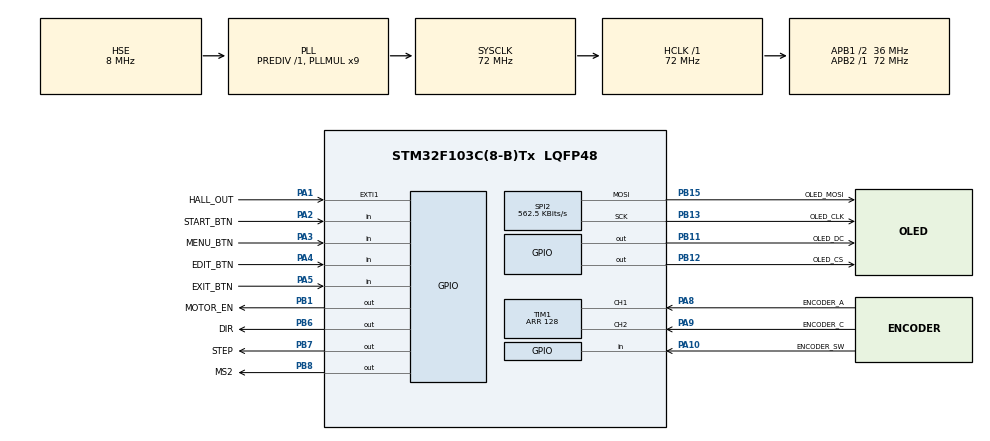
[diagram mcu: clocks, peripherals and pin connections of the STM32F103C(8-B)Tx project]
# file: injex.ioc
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FREERTOS.BinarySemaphores01=stopMoveByTime;suspendMoveByTime
FREERTOS.Queues01=buttonEvents,16,uint16_t,NULL;encoderEvents,16,uint16_t,NULL
FREERTOS.Tasks01=defaultTask,0,64,StartDefaultTask,Default;buttonScanTask,-2,128,buttonScanFunc,As external;guiTask,0,128,guiFunc,As external;motorTask,1,64,motorFunc,As external
FREERTOS.Timers01=elapsedTimer,elapsedTimerCallback,osTimerPeriodic,As external;moveTimer,moveTimerCallback,osTimerPeriodic,As external
FREERTOS.configMINIMAL_STACK_SIZE=64
FREERTOS.configTIMER_QUEUE_LENGTH=20
FREERTOS.configTIMER_TASK_PRIORITY=4
FREERTOS.configTOTAL_HEAP_SIZE=6072
FREERTOS.configUSE_TIMERS=1
Mcu.Family=STM32F1
Mcu.Name=STM32F103C(8-B)Tx
Mcu.Package=LQFP48
NVIC.EXTI1_IRQn=true\:7\:0\:true
NVIC.PriorityGroup=NVIC_PRIORITYGROUP_4
NVIC.TIM2_IRQn=true\:15\:0\:true
PA1.GPIO_Label=HALL_OUT
PA1.GPIO_ModeDefaultEXTI=GPIO_MODE_IT_RISING_FALLING
PA1.GPIO_PuPd=GPIO_PULLUP
PA1.Signal=GPXTI1
PA10.GPIO_Label=ENCODER_SW
PA10.GPIO_PuPd=GPIO_PULLDOWN
PA10.Signal=GPIO_Input
PA13.Mode=Serial_Wire
PA13.Signal=SYS_JTMS-SWDIO
PA14.Mode=Serial_Wire
PA14.Signal=SYS_JTCK-SWCLK
PA2.GPIO_Label=START_BTN
PA2.GPIO_PuPd=GPIO_PULLDOWN
PA2.Signal=GPIO_Input
PA3.GPIO_Label=MENU_BTN
PA3.GPIO_PuPd=GPIO_PULLDOWN
PA3.Signal=GPIO_Input
PA4.GPIO_Label=EDIT_BTN
PA4.GPIO_PuPd=GPIO_PULLDOWN
PA4.Signal=GPIO_Input
PA5.GPIO_Label=EXIT_BTN
PA5.GPIO_PuPd=GPIO_PULLDOWN
PA5.Signal=GPIO_Input
PA8.GPIO_Label=ENCODER_A
PA8.GPIO_PuPd=GPIO_PULLUP
PA8.Signal=S_TIM1_CH1
PA9.GPIO_Label=ENCODER_C
PA9.GPIO_PuPd=GPIO_PULLUP
PA9.Signal=S_TIM1_CH2
PB1.GPIO_Label=MOTOR_EN
PB1.GPIO_Speed=GPIO_SPEED_HIGH
PB1.Signal=GPIO_Output
PB11.GPIO_Label=OLED_DC
PB11.GPIO_Speed=GPIO_SPEED_HIGH
PB11.Signal=GPIO_Output
PB12.GPIO_Label=OLED_CS
PB12.GPIO_Speed=GPIO_SPEED_HIGH
PB12.Signal=GPIO_Output
PB13.GPIO_Label=OLED_CLK
PB13.Mode=TX_Only_Simplex_Unidirect_Master
PB13.Signal=SPI2_SCK
PB15.GPIO_Label=OLED_MOSI
PB15.Mode=TX_Only_Simplex_Unidirect_Master
PB15.Signal=SPI2_MOSI
PB6.GPIO_Label=DIR
PB6.GPIO_Speed=GPIO_SPEED_HIGH
PB6.Signal=GPIO_Output
PB7.GPIO_Label=STEP
PB7.GPIO_Speed=GPIO_SPEED_HIGH
PB7.Signal=GPIO_Output
PB8.GPIO_Label=MS2
PB8.GPIO_Speed=GPIO_SPEED_HIGH
PB8.Signal=GPIO_Output
PD0-OSC_IN.Mode=HSE-External-Oscillator
PD0-OSC_IN.Signal=RCC_OSC_IN
PD1-OSC_OUT.Mode=HSE-External-Oscillator
PD1-OSC_OUT.Signal=RCC_OSC_OUT
ProjectManager.HeapSize=0x400
ProjectManager.StackSize=0x200
ProjectManager.TargetToolchain=SW4STM32
RCC.AHBFreq_Value=72000000
RCC.APB1CLKDivider=RCC_HCLK_DIV2
RCC.APB1Freq_Value=36000000
RCC.APB1TimFreq_Value=72000000
RCC.APB2Freq_Value=72000000
RCC.APB2TimFreq_Value=72000000
RCC.HCLKFreq_Value=72000000
RCC.HSIState=RCC_HSI_ON
RCC.PLLMUL=RCC_PLL_MUL9
RCC.PLLSourceVirtual=RCC_PLLSOURCE_HSE
RCC.SYSCLKFreq_VALUE=72000000
RCC.SYSCLKSource=RCC_SYSCLKSOURCE_PLLCLK
RCC.USBFreq_Value=72000000
SH.S_TIM1_CH1.0=TIM1_CH1,Encoder_Interface
SH.S_TIM1_CH2.0=TIM1_CH2,Encoder_Interface
SPI2.BaudRatePrescaler=SPI_BAUDRATEPRESCALER_64
SPI2.CalculateBaudRate=562.5 KBits/s
SPI2.Mode=SPI_MODE_MASTER
TIM1.ClockDivision=TIM_CLOCKDIVISION_DIV2
TIM1.EncoderMode=TIM_ENCODERMODE_TI12
TIM1.IC1Filter=5
TIM1.IC1Polarity=TIM_ICPOLARITY_FALLING
TIM1.IC2Filter=5
TIM1.IC2Polarity=TIM_ICPOLARITY_FALLING
TIM1.Period=128
TIM2.Period=100
TIM2.Prescaler=720
VP_FREERTOS_VS_ENABLE.Mode=Enabled
VP_TIM2_VS_ClockSourceINT.Mode=Internal
board=injex

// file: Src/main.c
/**
  ******************************************************************************
  * File Name          : main.c
  * Description        : Main program body
  ******************************************************************************
  *
  * COPYRIGHT(c) 2016 STMicroelectronics
  *
  * Redistribution and use in source and binary forms, with or without modification,
  * are permitted provided that the following conditions are met:
  *   1. Redistributions of source code must retain the above copyright notice,
  *      this list of conditions and the following disclaimer.
  *   2. Redistributions in binary form must reproduce the above copyright notice,
  *      this list of conditions and the following disclaimer in the documentation
  *      and/or other materials provided with the distribution.
  *   3. Neither the name of STMicroelectronics nor the names of its contributors
  *      may be used to endorse or promote products derived from this software
  *      without specific prior written permission.
  *
  * THIS SOFTWARE IS PROVIDED BY THE COPYRIGHT HOLDERS AND CONTRIBUTORS "AS IS"
  * AND ANY EXPRESS OR IMPLIED WARRANTIES, INCLUDING, BUT NOT LIMITED TO, THE
  * IMPLIED WARRANTIES OF MERCHANTABILITY AND FITNESS FOR A PARTICULAR PURPOSE ARE
  * DISCLAIMED. IN NO EVENT SHALL THE COPYRIGHT HOLDER OR CONTRIBUTORS BE LIABLE
  * FOR ANY DIRECT, INDIRECT, INCIDENTAL, SPECIAL, EXEMPLARY, OR CONSEQUENTIAL
  * DAMAGES (INCLUDING, BUT NOT LIMITED TO, PROCUREMENT OF SUBSTITUTE GOODS OR
  * SERVICES; LOSS OF USE, DATA, OR PROFITS; OR BUSINESS INTERRUPTION) HOWEVER
  * CAUSED AND ON ANY THEORY OF LIABILITY, WHETHER IN CONTRACT, STRICT LIABILITY,
  * OR TORT (INCLUDING NEGLIGENCE OR OTHERWISE) ARISING IN ANY WAY OUT OF THE USE
  * OF THIS SOFTWARE, EVEN IF ADVISED OF THE POSSIBILITY OF SUCH DAMAGE.
  *
  ******************************************************************************
  */
#include "stm32f1xx_hal.h"
#include "cmsis_os.h"

/* USER CODE BEGIN Includes */
#include "motor_control.h"
#include "gui.h"
/* USER CODE END Includes */

SPI_HandleTypeDef hspi2;

TIM_HandleTypeDef htim1;
TIM_HandleTypeDef htim2;

osThreadId defaultTaskHandle;
osThreadId buttonScanTaskHandle;
osThreadId guiTaskHandle;
osThreadId motorTaskHandle;
osMessageQId buttonEventsHandle;
osMessageQId encoderEventsHandle;
osTimerId elapsedTimerHandle;
osTimerId moveTimerHandle;
osSemaphoreId stopMoveByTimeHandle;
osSemaphoreId suspendMoveByTimeHandle;

/* USER CODE BEGIN PV */
QueueHandle_t xInputEvents;
QueueHandle_t xMotorEvents;
/* Private variables ---------------------------------------------------------*/

/* USER CODE END PV */

void SystemClock_Config(void);
static void MX_GPIO_Init(void);
static void MX_SPI2_Init(void);
static void MX_TIM1_Init(void);
static void MX_TIM2_Init(void);
void StartDefaultTask(void const * argument);
extern void buttonScanFunc(void const * argument);
extern void guiFunc(void const * argument);
extern void motorFunc(void const * argument);
extern void elapsedTimerCallback(void const * argument);
extern void moveTimerCallback(void const * argument);

/* USER CODE BEGIN PFP */
/* Private function prototypes -----------------------------------------------*/
/* USER CODE END PFP */

int main(void)
{

  /* MCU Configuration----------------------------------------------------------*/

  /* Reset of all peripherals, Initializes the Flash interface and the Systick. */
  HAL_Init();

  /* Configure the system clock */
  SystemClock_Config();

  /* Initialize all configured peripherals */
  MX_GPIO_Init();
  MX_SPI2_Init();
  MX_TIM1_Init();
  MX_TIM2_Init();

  /* USER CODE BEGIN 2 */
	InitMotor();
	HAL_TIM_Encoder_Start(&htim1,TIM_CHANNEL_ALL);

  /* USER CODE END 2 */

  /* Create the semaphores(s) */
  /* definition and creation of stopMoveByTime */
  osSemaphoreDef(stopMoveByTime);
  stopMoveByTimeHandle = osSemaphoreCreate(osSemaphore(stopMoveByTime), 1);

  /* definition and creation of suspendMoveByTime */
  osSemaphoreDef(suspendMoveByTime);
  suspendMoveByTimeHandle = osSemaphoreCreate(osSemaphore(suspendMoveByTime), 1);

  /* USER CODE BEGIN RTOS_SEMAPHORES */
  xSemaphoreTake(stopMoveByTimeHandle, 0);
  xSemaphoreTake(suspendMoveByTimeHandle, 0);
	/* add semaphores, ... */
  /* USER CODE END RTOS_SEMAPHORES */

  /* Create the timer(s) */
  /* definition and creation of elapsedTimer */
  osTimerDef(elapsedTimer, elapsedTimerCallback);
  elapsedTimerHandle = osTimerCreate(osTimer(elapsedTimer), osTimerPeriodic, NULL);

  /* definition and creation of moveTimer */
  osTimerDef(moveTimer, moveTimerCallback);
  moveTimerHandle = osTimerCreate(osTimer(moveTimer), osTimerPeriodic, NULL);

  /* Create the thread(s) */
  /* definition and creation of defaultTask */
  osThreadDef(defaultTask, StartDefaultTask, osPriorityNormal, 0, 64);
  defaultTaskHandle = osThreadCreate(osThread(defaultTask), NULL);

  /* definition and creation of buttonScanTask */
  osThreadDef(buttonScanTask, buttonScanFunc, osPriorityLow, 0, 128);
  buttonScanTaskHandle = osThreadCreate(osThread(buttonScanTask), NULL);

  /* definition and creation of guiTask */
  osThreadDef(guiTask, guiFunc, osPriorityNormal, 0, 128);
  guiTaskHandle = osThreadCreate(osThread(guiTask), NULL);

  /* definition and creation of motorTask */
  osThreadDef(motorTask, motorFunc, osPriorityAboveNormal, 0, 64);
  motorTaskHandle = osThreadCreate(osThread(motorTask), NULL);

  /* Create the queue(s) */
  /* definition and creation of buttonEvents */
  osMessageQDef(buttonEvents, 16, uint16_t);
  buttonEventsHandle = osMessageCreate(osMessageQ(buttonEvents), NULL);

  /* definition and creation of encoderEvents */
  osMessageQDef(encoderEvents, 16, uint16_t);
  encoderEventsHandle = osMessageCreate(osMessageQ(encoderEvents), NULL);

  /* USER CODE BEGIN RTOS_QUEUES */
	/* add queues, ... */
  xInputEvents = xQueueCreate( 8, sizeof( struct Event ) );
  xMotorEvents = xQueueCreate( 4, sizeof( struct MotorEvent ) );
  /* USER CODE END RTOS_QUEUES */

  /* Start scheduler */
  osKernelStart();

  /* We should never get here as control is now taken by the scheduler */

  /* Infinite loop */
	while (1)
	{

	}

}

/** System Clock Configuration
*/
void SystemClock_Config(void)
{

  RCC_OscInitTypeDef RCC_OscInitStruct;
  RCC_ClkInitTypeDef RCC_ClkInitStruct;

  RCC_OscInitStruct.OscillatorType = RCC_OSCILLATORTYPE_HSE;
  RCC_OscInitStruct.HSEState = RCC_HSE_ON;
  RCC_OscInitStruct.HSEPredivValue = RCC_HSE_PREDIV_DIV1;
  RCC_OscInitStruct.PLL.PLLState = RCC_PLL_ON;
  RCC_OscInitStruct.PLL.PLLSource = RCC_PLLSOURCE_HSE;
  RCC_OscInitStruct.PLL.PLLMUL = RCC_PLL_MUL9;
  HAL_RCC_OscConfig(&RCC_OscInitStruct);

  RCC_ClkInitStruct.ClockType = RCC_CLOCKTYPE_HCLK|RCC_CLOCKTYPE_SYSCLK
                              |RCC_CLOCKTYPE_PCLK1|RCC_CLOCKTYPE_PCLK2;
  RCC_ClkInitStruct.SYSCLKSource = RCC_SYSCLKSOURCE_PLLCLK;
  RCC_ClkInitStruct.AHBCLKDivider = RCC_SYSCLK_DIV1;
  RCC_ClkInitStruct.APB1CLKDivider = RCC_HCLK_DIV2;
  RCC_ClkInitStruct.APB2CLKDivider = RCC_HCLK_DIV1;
  HAL_RCC_ClockConfig(&RCC_ClkInitStruct, FLASH_LATENCY_2);

  HAL_SYSTICK_Config(HAL_RCC_GetHCLKFreq()/1000);

  HAL_SYSTICK_CLKSourceConfig(SYSTICK_CLKSOURCE_HCLK);

  /* SysTick_IRQn interrupt configuration */
  HAL_NVIC_SetPriority(SysTick_IRQn, 15, 0);
}

/* SPI2 init function */
void MX_SPI2_Init(void)
{

  hspi2.Instance = SPI2;
  hspi2.Init.Mode = SPI_MODE_MASTER;
  hspi2.Init.Direction = SPI_DIRECTION_2LINES;
  hspi2.Init.DataSize = SPI_DATASIZE_8BIT;
  hspi2.Init.CLKPolarity = SPI_POLARITY_LOW;
  hspi2.Init.CLKPhase = SPI_PHASE_1EDGE;
  hspi2.Init.NSS = SPI_NSS_SOFT;
  hspi2.Init.BaudRatePrescaler = SPI_BAUDRATEPRESCALER_64;
  hspi2.Init.FirstBit = SPI_FIRSTBIT_MSB;
  hspi2.Init.TIMode = SPI_TIMODE_DISABLED;
  hspi2.Init.CRCCalculation = SPI_CRCCALCULATION_DISABLED;
  hspi2.Init.CRCPolynomial = 10;
  HAL_SPI_Init(&hspi2);

}

/* TIM1 init function */
void MX_TIM1_Init(void)
{

  TIM_Encoder_InitTypeDef sConfig;
  TIM_MasterConfigTypeDef sMasterConfig;

  htim1.Instance = TIM1;
  htim1.Init.Prescaler = 0;
  htim1.Init.CounterMode = TIM_COUNTERMODE_UP;
  htim1.Init.Period = 128;
  htim1.Init.ClockDivision = TIM_CLOCKDIVISION_DIV2;
  htim1.Init.RepetitionCounter = 0;
  sConfig.EncoderMode = TIM_ENCODERMODE_TI12;
  sConfig.IC1Polarity = TIM_ICPOLARITY_FALLING;
  sConfig.IC1Selection = TIM_ICSELECTION_DIRECTTI;
  sConfig.IC1Prescaler = TIM_ICPSC_DIV1;
  sConfig.IC1Filter = 5;
  sConfig.IC2Polarity = TIM_ICPOLARITY_FALLING;
  sConfig.IC2Selection = TIM_ICSELECTION_DIRECTTI;
  sConfig.IC2Prescaler = TIM_ICPSC_DIV1;
  sConfig.IC2Filter = 5;
  HAL_TIM_Encoder_Init(&htim1, &sConfig);

  sMasterConfig.MasterOutputTrigger = TIM_TRGO_RESET;
  sMasterConfig.MasterSlaveMode = TIM_MASTERSLAVEMODE_DISABLE;
  HAL_TIMEx_MasterConfigSynchronization(&htim1, &sMasterConfig);

}

/* TIM2 init function */
void MX_TIM2_Init(void)
{

  TIM_ClockConfigTypeDef sClockSourceConfig;
  TIM_MasterConfigTypeDef sMasterConfig;

  htim2.Instance = TIM2;
  htim2.Init.Prescaler = 720;
  htim2.Init.CounterMode = TIM_COUNTERMODE_UP;
  htim2.Init.Period = 100;
  htim2.Init.ClockDivision = TIM_CLOCKDIVISION_DIV1;
  HAL_TIM_Base_Init(&htim2);

  sClockSourceConfig.ClockSource = TIM_CLOCKSOURCE_INTERNAL;
  HAL_TIM_ConfigClockSource(&htim2, &sClockSourceConfig);

  sMasterConfig.MasterOutputTrigger = TIM_TRGO_RESET;
  sMasterConfig.MasterSlaveMode = TIM_MASTERSLAVEMODE_DISABLE;
  HAL_TIMEx_MasterConfigSynchronization(&htim2, &sMasterConfig);

}

/** Configure pins as
        * Analog
        * Input
        * Output
        * EVENT_OUT
        * EXTI
*/
void MX_GPIO_Init(void)
{

  GPIO_InitTypeDef GPIO_InitStruct;

  /* GPIO Ports Clock Enable */
  __GPIOD_CLK_ENABLE();
  __GPIOA_CLK_ENABLE();
  __GPIOB_CLK_ENABLE();

  /*Configure GPIO pin : HALL_OUT_Pin */
  GPIO_InitStruct.Pin = HALL_OUT_Pin;
  GPIO_InitStruct.Mode = GPIO_MODE_IT_RISING_FALLING;
  GPIO_InitStruct.Pull = GPIO_PULLUP;
  HAL_GPIO_Init(HALL_OUT_GPIO_Port, &GPIO_InitStruct);

  /*Configure GPIO pins : START_BTN_Pin MENU_BTN_Pin EDIT_BTN_Pin EXIT_BTN_Pin
                           ENCODER_SW_Pin */
  GPIO_InitStruct.Pin = START_BTN_Pin|MENU_BTN_Pin|EDIT_BTN_Pin|EXIT_BTN_Pin
                          |ENCODER_SW_Pin;
  GPIO_InitStruct.Mode = GPIO_MODE_INPUT;
  GPIO_InitStruct.Pull = GPIO_PULLDOWN;
  HAL_GPIO_Init(GPIOA, &GPIO_InitStruct);

  /*Configure GPIO pins : MOTOR_EN_Pin OLED_DC_Pin OLED_CS_Pin DIR_Pin
                           STEP_Pin MS2_Pin */
  GPIO_InitStruct.Pin = MOTOR_EN_Pin|OLED_DC_Pin|OLED_CS_Pin|DIR_Pin
                          |STEP_Pin|MS2_Pin;
  GPIO_InitStruct.Mode = GPIO_MODE_OUTPUT_PP;
  GPIO_InitStruct.Speed = GPIO_SPEED_HIGH;
  HAL_GPIO_Init(GPIOB, &GPIO_InitStruct);

  /*Configure GPIO pin Output Level */
  HAL_GPIO_WritePin(GPIOB, MOTOR_EN_Pin|OLED_DC_Pin|OLED_CS_Pin|DIR_Pin
                          |STEP_Pin|MS2_Pin, GPIO_PIN_RESET);

  /* EXTI interrupt init*/
  HAL_NVIC_SetPriority(EXTI1_IRQn, 7, 0);
  HAL_NVIC_EnableIRQ(EXTI1_IRQn);

}

/* StartDefaultTask function */
void StartDefaultTask(void const * argument)
{

	for(;;)
	{
		osDelay(1);
	}
}

/************************ (C) COPYRIGHT STMicroelectronics *****END OF FILE****/
